VERSION ""

NS_ :

BS_:

BU_: BMS Third_Party_Device

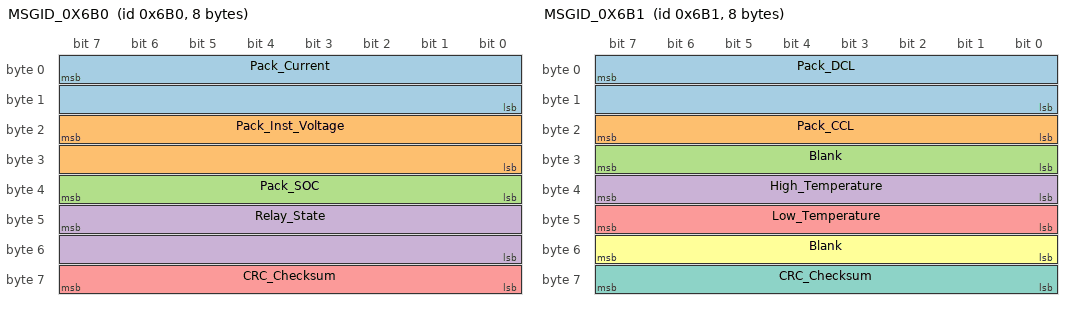
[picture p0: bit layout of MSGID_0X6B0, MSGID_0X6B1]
BO_ 1712 MSGID_0X6B0: 8 BMS
 SG_ Pack_Current : 7|16@0+ (0.1,0) [0|0] "Amps"  Third_Party_Device
 SG_ Pack_Inst_Voltage : 23|16@0+ (0.1,0) [0|0] "Volts"  Third_Party_Device
 SG_ Pack_SOC : 39|8@0+ (0.5,0) [0|0] "Percent"  Third_Party_Device
 SG_ Relay_State : 47|16@0+ (1.0,0) [0|0] ""  Third_Party_Device
 SG_ CRC_Checksum : 63|8@0+ (1.0,1720) [0|0] ""  Third_Party_Device

BO_ 1713 MSGID_0X6B1: 8 BMS
 SG_ Pack_DCL : 7|16@0+ (1.0,0) [0|0] "Amps"  Third_Party_Device
 SG_ Pack_CCL : 23|8@0+ (1.0,0) [0|0] "Amps"  Third_Party_Device
 SG_ Blank : 31|8@0+ (1.0,0) [0|0] ""  Third_Party_Device
 SG_ High_Temperature : 39|8@0+ (1.0,0) [0|0] "Celsius"  Third_Party_Device
 SG_ Low_Temperature : 47|8@0+ (1.0,0) [0|0] "Celsius"  Third_Party_Device
 SG_ Blank : 55|8@0+ (1.0,0) [0|0] ""  Third_Party_Device
 SG_ CRC_Checksum : 63|8@0+ (1.0,1721) [0|0] ""  Third_Party_Device

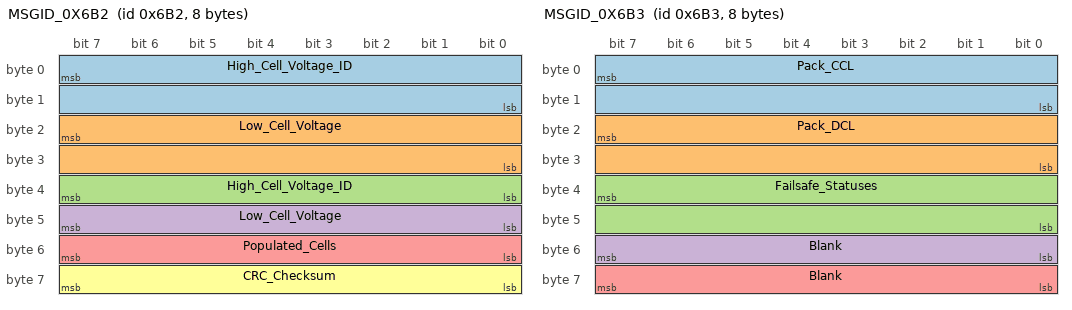
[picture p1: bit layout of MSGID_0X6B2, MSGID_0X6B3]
BO_ 1714 MSGID_0X6B2: 8 BMS
 SG_ High_Cell_Voltage_ID : 7|16@0+ (1.0,0) [0|0] "ID"  Third_Party_Device
 SG_ Low_Cell_Voltage : 23|16@0+ (1.0E-4,0) [0|0] "Volts"  Third_Party_Device
 SG_ High_Cell_Voltage_ID : 39|8@0+ (1.0,0) [0|0] "ID"  Third_Party_Device
 SG_ Low_Cell_Voltage : 47|8@0+ (1.0E-4,0) [0|0] "Volts"  Third_Party_Device
 SG_ Populated_Cells : 55|8@0+ (1.0,0) [0|0] "Num"  Third_Party_Device
 SG_ CRC_Checksum : 63|8@0+ (1.0,0) [0|0] ""  Third_Party_Device

BO_ 1715 MSGID_0X6B3: 8 BMS
 SG_ Pack_CCL : 7|16@0+ (1.0,0) [0|0] "Amps"  Third_Party_Device
 SG_ Pack_DCL : 23|16@0+ (1.0,0) [0|0] "Amps"  Third_Party_Device
 SG_ Failsafe_Statuses : 39|16@0+ (1.0,0) [0|0] ""  Third_Party_Device
 SG_ Blank : 55|8@0+ (1.0,0) [0|0] ""  Third_Party_Device
 SG_ Blank : 63|8@0+ (1.0,0) [0|0] ""  Third_Party_Device

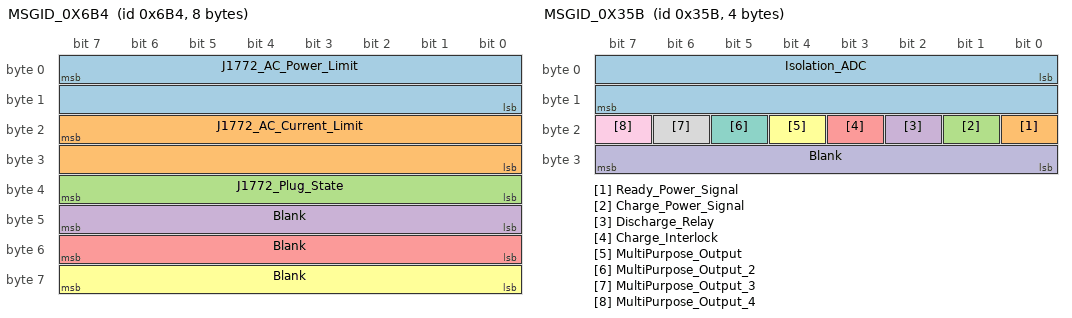
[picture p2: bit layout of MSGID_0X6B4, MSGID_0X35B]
BO_ 1716 MSGID_0X6B4: 8 BMS
 SG_ J1772_AC_Power_Limit : 7|16@0+ (1.0,0) [0|0] "Watts"  Third_Party_Device
 SG_ J1772_AC_Current_Limit : 23|16@0+ (1.0,0) [0|0] "Amps"  Third_Party_Device
 SG_ J1772_Plug_State : 39|8@0+ (1.0,0) [0|0] ""  Third_Party_Device
 SG_ Blank : 47|8@0+ (1.0,0) [0|0] ""  Third_Party_Device
 SG_ Blank : 55|8@0+ (1.0,0) [0|0] ""  Third_Party_Device
 SG_ Blank : 63|8@0+ (1.0,0) [0|0] ""  Third_Party_Device

BO_ 859 MSGID_0X35B: 4 BMS
 SG_ Isolation_ADC : 0|16@1+ (1.0,0) [0|0] ""  Third_Party_Device
 SG_ Ready_Power_Signal : 16|1@1+ (1.0,0) [0|1] ""  Third_Party_Device
 SG_ Charge_Power_Signal : 17|1@1+ (1.0,0) [0|1] ""  Third_Party_Device
 SG_ Discharge_Relay : 18|1@1+ (1.0,0) [0|1] ""  Third_Party_Device
 SG_ Charge_Interlock : 19|1@1+ (1.0,0) [0|1] ""  Third_Party_Device
 SG_ MultiPurpose_Output : 20|1@1+ (1.0,0) [0|1] ""  Third_Party_Device
 SG_ MultiPurpose_Output_2 : 21|1@1+ (1.0,0) [0|1] ""  Third_Party_Device
 SG_ MultiPurpose_Output_3 : 22|1@1+ (1.0,0) [0|1] ""  Third_Party_Device
 SG_ MultiPurpose_Output_4 : 23|1@1+ (1.0,0) [0|1] ""  Third_Party_Device
 SG_ Blank : 24|8@1+ (1.0,0) [0|0] ""  Third_Party_Device

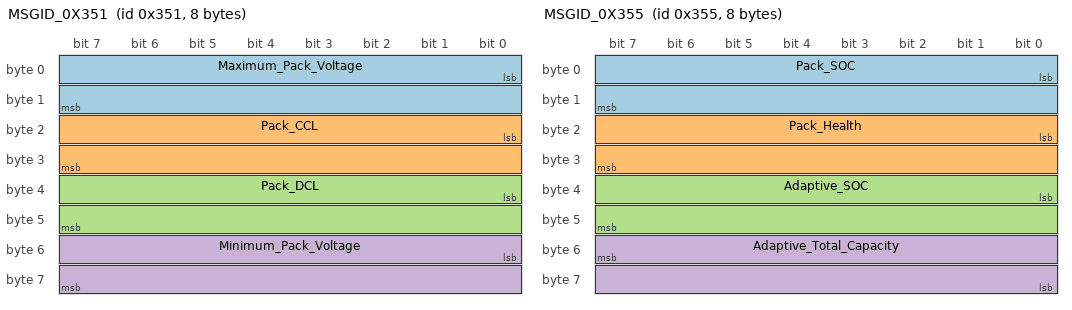
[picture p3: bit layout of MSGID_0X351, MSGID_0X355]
BO_ 849 MSGID_0X351: 8 BMS
 SG_ Maximum_Pack_Voltage : 0|16@1+ (0.1,0) [0|0] "Volts"  Third_Party_Device
 SG_ Pack_CCL : 16|16@1+ (0.1,0) [0|0] "Amps"  Third_Party_Device
 SG_ Pack_DCL : 32|16@1+ (0.1,0) [0|0] "Amps"  Third_Party_Device
 SG_ Minimum_Pack_Voltage : 48|16@1+ (0.1,0) [0|0] "Volts"  Third_Party_Device

BO_ 853 MSGID_0X355: 8 BMS
 SG_ Pack_SOC : 0|16@1+ (1.0,0) [0|0] "Percent"  Third_Party_Device
 SG_ Pack_Health : 16|16@1+ (1.0,0) [0|0] "Percent"  Third_Party_Device
 SG_ Adaptive_SOC : 32|16@1+ (0.1,0) [0|0] "Percent"  Third_Party_Device
 SG_ Adaptive_Total_Capacity : 55|16@0+ (0.1,0) [0|0] "Amphours"  Third_Party_Device

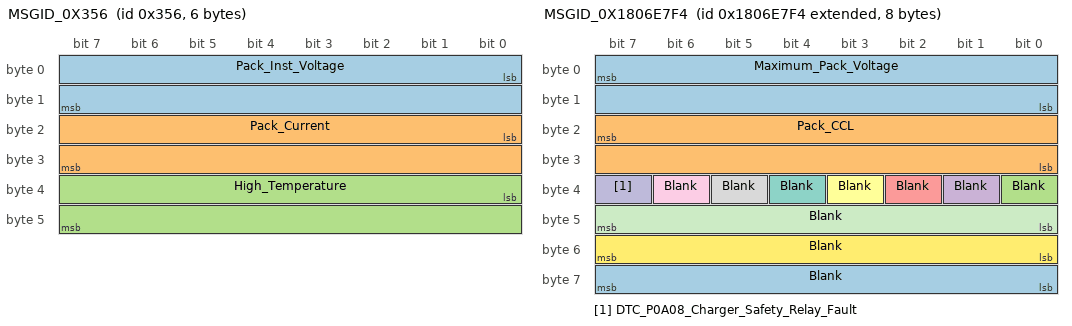
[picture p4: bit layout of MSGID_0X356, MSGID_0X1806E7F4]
BO_ 854 MSGID_0X356: 6 BMS
 SG_ Pack_Inst_Voltage : 0|16@1+ (0.1,0) [0|0] "Volts"  Third_Party_Device
 SG_ Pack_Current : 16|16@1- (0.1,0) [0|0] "Amps"  Third_Party_Device
 SG_ High_Temperature : 32|16@1+ (0.1,0) [0|0] "Celsius"  Third_Party_Device

BO_ 858 MSGID_0X35A: 4 BMS
 SG_ DTC_Flags_1 : 0|16@1+ (1.0,0) [0|0] ""  Third_Party_Device
 SG_ DTC_Flags_2 : 16|16@1+ (1.0,0) [0|0] ""  Third_Party_Device

BO_ 855 MSGID_0X357: 3 Third_Party_Device
 SG_ Isolation_Relay_Override : 0|8@1+ (1.0,0) [0|0] "ON/OFF"  BMS
 SG_ AC_Current_Limit : 8|16@1+ (1.0,0) [0|0] "Amps"  BMS

BO_ 2550589428 MSGID_0X1806E7F4: 8 BMS
 SG_ Maximum_Pack_Voltage : 7|16@0+ (0.1,0) [0|0] "Volts"  Third_Party_Device
 SG_ Pack_CCL : 23|16@0+ (0.1,0) [0|0] "Amps"  Third_Party_Device
 SG_ Blank : 32|1@1+ (1.0,0) [0|1] ""  Third_Party_Device
 SG_ Blank : 33|1@1+ (1.0,0) [0|1] ""  Third_Party_Device
 SG_ Blank : 34|1@1+ (1.0,0) [0|1] ""  Third_Party_Device
 SG_ Blank : 35|1@1+ (1.0,0) [0|1] ""  Third_Party_Device
 SG_ Blank : 36|1@1+ (1.0,0) [0|1] ""  Third_Party_Device
 SG_ Blank : 37|1@1+ (1.0,0) [0|1] ""  Third_Party_Device
 SG_ Blank : 38|1@1+ (1.0,0) [0|1] ""  Third_Party_Device
 SG_ DTC_P0A08_Charger_Safety_Relay_Fault : 39|1@1+ (1.0,0) [0|1] ""  Third_Party_Device
 SG_ Blank : 47|8@0+ (0.1,0) [0|0] ""  Third_Party_Device
 SG_ Blank : 55|8@0+ (1.0,0) [0|0] ""  Third_Party_Device
 SG_ Blank : 63|8@0+ (1.0,0) [0|0] ""  Third_Party_Device

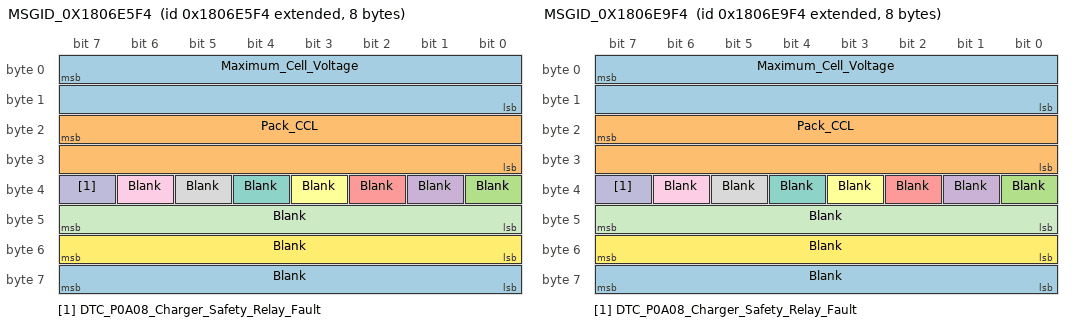
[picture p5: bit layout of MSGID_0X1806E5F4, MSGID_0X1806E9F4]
BO_ 2550588916 MSGID_0X1806E5F4: 8 BMS
 SG_ Maximum_Cell_Voltage : 7|16@0+ (0.001388888888888889,0) [0|0] "Volts"  Third_Party_Device
 SG_ Pack_CCL : 23|16@0+ (0.1,0) [0|0] "Amps"  Third_Party_Device
 SG_ Blank : 32|1@1+ (1.0,0) [0|1] ""  Third_Party_Device
 SG_ Blank : 33|1@1+ (1.0,0) [0|1] ""  Third_Party_Device
 SG_ Blank : 34|1@1+ (1.0,0) [0|1] ""  Third_Party_Device
 SG_ Blank : 35|1@1+ (1.0,0) [0|1] ""  Third_Party_Device
 SG_ Blank : 36|1@1+ (1.0,0) [0|1] ""  Third_Party_Device
 SG_ Blank : 37|1@1+ (1.0,0) [0|1] ""  Third_Party_Device
 SG_ Blank : 38|1@1+ (1.0,0) [0|1] ""  Third_Party_Device
 SG_ DTC_P0A08_Charger_Safety_Relay_Fault : 39|1@1+ (1.0,0) [0|1] ""  Third_Party_Device
 SG_ Blank : 47|8@0+ (0.1,0) [0|0] ""  Third_Party_Device
 SG_ Blank : 55|8@0+ (1.0,0) [0|0] ""  Third_Party_Device
 SG_ Blank : 63|8@0+ (1.0,0) [0|0] ""  Third_Party_Device

BO_ 2550589940 MSGID_0X1806E9F4: 8 BMS
 SG_ Maximum_Cell_Voltage : 7|16@0+ (0.001388888888888889,0) [0|0] "Volts"  Third_Party_Device
 SG_ Pack_CCL : 23|16@0+ (0.1,0) [0|0] "Amps"  Third_Party_Device
 SG_ Blank : 32|1@1+ (1.0,0) [0|1] ""  Third_Party_Device
 SG_ Blank : 33|1@1+ (1.0,0) [0|1] ""  Third_Party_Device
 SG_ Blank : 34|1@1+ (1.0,0) [0|1] ""  Third_Party_Device
 SG_ Blank : 35|1@1+ (1.0,0) [0|1] ""  Third_Party_Device
 SG_ Blank : 36|1@1+ (1.0,0) [0|1] ""  Third_Party_Device
 SG_ Blank : 37|1@1+ (1.0,0) [0|1] ""  Third_Party_Device
 SG_ Blank : 38|1@1+ (1.0,0) [0|1] ""  Third_Party_Device
 SG_ DTC_P0A08_Charger_Safety_Relay_Fault : 39|1@1+ (1.0,0) [0|1] ""  Third_Party_Device
 SG_ Blank : 47|8@0+ (1.0,0) [0|0] ""  Third_Party_Device
 SG_ Blank : 55|8@0+ (1.0,0) [0|0] ""  Third_Party_Device
 SG_ Blank : 63|8@0+ (1.0,0) [0|0] ""  Third_Party_Device

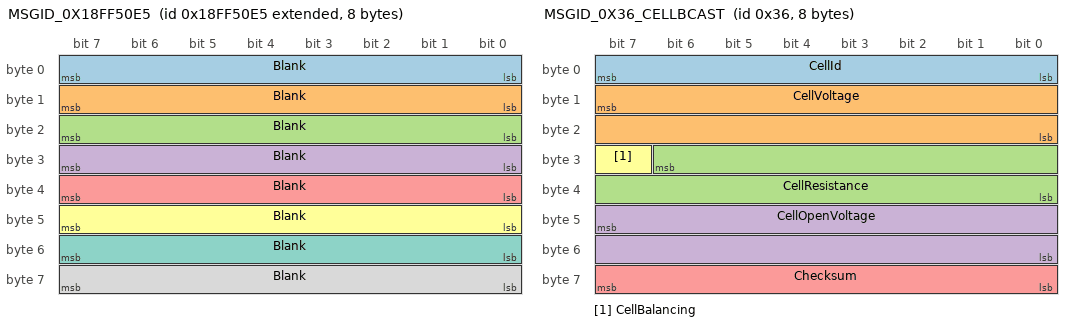
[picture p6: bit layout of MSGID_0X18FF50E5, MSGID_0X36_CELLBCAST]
BO_ 2566869221 MSGID_0X18FF50E5: 8 Third_Party_Device
 SG_ Blank : 7|8@0+ (1.0,0) [0|0] ""  BMS
 SG_ Blank : 15|8@0+ (1.0,0) [0|0] ""  BMS
 SG_ Blank : 23|8@0+ (1.0,0) [0|0] ""  BMS
 SG_ Blank : 31|8@0+ (1.0,0) [0|0] ""  BMS
 SG_ Blank : 39|8@0+ (1.0,0) [0|0] ""  BMS
 SG_ Blank : 47|8@0+ (1.0,0) [0|0] ""  BMS
 SG_ Blank : 55|8@0+ (1.0,0) [0|0] ""  BMS
 SG_ Blank : 63|8@0+ (1.0,0) [0|0] ""  BMS

BO_ 54 MSGID_0X36_CELLBCAST: 8 BMS
 SG_ CellId : 7|8@0+ (1,0) [0|0] "#" Third_Party_Device
 SG_ CellVoltage : 15|16@0+ (0.0001,0) [0|0] "Volts" Third_Party_Device
 SG_ CellResistance : 30|15@0+ (0.01,0) [0|0] "mOhms" Third_Party_Device
 SG_ CellOpenVoltage : 47|16@0+ (0.0001,0) [0|0] "Volts" Third_Party_Device
 SG_ Checksum : 63|8@0+ (1,0) [0|0] "" Third_Party_Device
 SG_ CellBalancing : 31|1@1+ (1,0) [0|0] "" Third_Party_Device
CM_ BO_ 1712 "This ID Transmits at 1000 ms.";
CM_ BO_ 1713 "This ID Transmits at 1000 ms.";
CM_ BO_ 1714 "This ID Transmits at 1000 ms.";
CM_ BO_ 1715 "This ID Transmits at 1000 ms.";
CM_ BO_ 1716 "This ID Transmits at 1000 ms.";
CM_ BO_ 859 "This ID Transmits at 504 ms.";
CM_ BO_ 849 "This ID Transmits at 104 ms.";
CM_ BO_ 853 "This ID Transmits at 104 ms.";
CM_ BO_ 854 "This ID Transmits at 104 ms.";
CM_ BO_ 858 "This ID Transmits at 504 ms.";
CM_ BO_ 2550589428 "This ID Transmits at 808 ms.";
CM_ BO_ 2550588916 "This ID Transmits at 808 ms.";
CM_ BO_ 2550589940 "This ID Transmits at 808 ms.";
CM_ BO_ 54 "This ID Transmits at 500 ms.";
CM_ SG_ 54 Checksum "Value = (0x36 + 8 + byte0 + byte1 + ... + byte6) & 0xFF";
